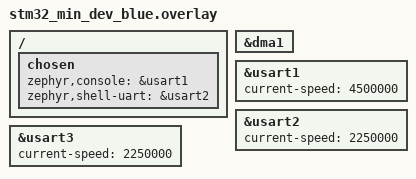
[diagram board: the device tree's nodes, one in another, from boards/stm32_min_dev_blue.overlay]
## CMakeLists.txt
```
cmake_minimum_required(VERSION 3.31)

find_package(Zephyr REQUIRED)
project(stm32f1-usb-gofast)

target_sources(app PRIVATE src/main.c src/usb.c)
```

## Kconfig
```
config GOFK_BULK_EP_MP
	int
	depends on USB_DEVICE_STACK
	default 512 if USB_DC_HAS_HS_SUPPORT
	default 64
	help
	  gofk bulk endpoint size

module = GOFK
module-str = gofk
source "subsys/logging/Kconfig.template.log_config"

source "Kconfig.zephyr"
```

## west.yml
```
manifest:
  remotes:
  - name: zephyrproject-rtos
    url-base: https://github.com/zephyrproject-rtos
  projects:
  - name: zephyr
    remote: zephyrproject-rtos
    revision: main
    import: true
```

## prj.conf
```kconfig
# Software Config

# Compilation

# Shell
CONFIG_SHELL=y
CONFIG_SHELL_MINIMAL=y

# Libraries
CONFIG_PICOLIBC=y
CONFIG_PICOLIBC_IO_FLOAT=n
CONFIG_PICOLIBC_IO_LONG_LONG=n
CONFIG_PICOLIBC_USE_MODULE=y
CONFIG_NET_BUF=y

# Timing
# CONFIG_TIMING_FUNCTIONS=y

# Debug
# CONFIG_ASSERT=n
# CONFIG_DEBUG=n
CONFIG_COMPILER_OPT="-ggdb3 -gdwarf-5 -Oz"

# console
# CONFIG_CONSOLE=n
# CONFIG_UART_CONSOLE=n

# logging
CONFIG_LOG=y
CONFIG_LOG_PRINTK=y
# CONFIG_LOG_SPEED=y
# CONFIG_LOG_BUFFER_SIZE=4096
# CONFIG_LOG_FRONTEND=y
# CONFIG_LOG_FRONTEND_DICT_UART=n
# CONFIG_LOG_FRONTEND_ONLY=y
# CONFIG_LOG_MEM_UTILIZATION=y
# CONFIG_LOG_FRONTEND_DICT_UART=y
# CONFIG_LOG_BACKEND_UART=y
# CONFIG_LOG_BACKEND_UART_ASYNC=y
# CONFIG_LOG_BACKEND_UART_OUTPUT_DICTIONARY_BIN=y
# CONFIG_LOG_BACKEND_UART_OUTPUT_DICTIONARY=y
# CONFIG_LOG_FMT_SECTION=y
# CONFIG_LOG_FRONTEND_DICT_UART=y
# CONFIG_LOG_FRONTEND_DICT_UART_BUFFER_SIZE=4096
# CONFIG_USB_DEVICE_LOG_LEVEL_INF=y
# CONFIG_USB_DEVICE_LOG_LEVEL_DBG=y
# CONFIG_USB_DEVICE_LOG_LEVEL_INF=y

# perf mon
# CONFIG_SCHED_THREAD_USAGE=y
# CONFIG_THREAD_ANALYZER=y
# CONFIG_THREAD_ANALYZER_USE_LOG=y
# CONFIG_THREAD_ANALYZER_AUTO=y
# CONFIG_THREAD_ANALYZER_AUTO_INTERVAL=10

# Hardware Config

# GPIO
CONFIG_GPIO=y

# UART
CONFIG_UART_ASYNC_API=n # need DMA
# CONFIG_UART_INTERRUPT_DRIVEN=n

# USB
CONFIG_USB_DEVICE_STACK=y
CONFIG_USB_DEVICE_VID=0x045a
CONFIG_USB_DEVICE_PID=0x6010
CONFIG_USB_DEVICE_MANUFACTURER="Pyongyang Chewing Gum Factory"
CONFIG_USB_DEVICE_PRODUCT="gofast"
```

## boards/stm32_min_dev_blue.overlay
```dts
/ {
	chosen {
		zephyr,console = &usart1;
		zephyr,shell-uart = &usart2;
	};
};

&dma1 {
	status = "okay";
};

// &usart1 {
// 	pinctrl-0 = <&usart1_tx_remap1_pb6 &usart1_rx_remap1_pb7>;
// 	current-speed = <3000000>;
// 	dmas = <&dma1 4 0x440>, <&dma1 5 0x480>;
// 	dma-names = "tx", "rx";
// };

&usart1 {
	current-speed = <4500000>;
};

&usart2 {
	current-speed = <2250000>;
};

&usart3 {
	current-speed = <2250000>;
};

// &usb {
// 	pinctrl-0 = <&usb_dm_pa11 &usb_dp_pa12>;
// 	pinctrl-1 = <&usb_dm_pa11_gpio_se0 &usb_dp_pa12_gpio_se0>;
// 	pinctrl-names = "default", "gpio_se0";
// 	num-bidir-endpoints = <3>;
// };
```

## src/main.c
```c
#include <stdio.h>

#include <zephyr/drivers/gpio.h>
#include <zephyr/kernel.h>
#include <zephyr/logging/log.h>
#include <zephyr/usb/usb_device.h>

LOG_MODULE_REGISTER(main);

/* 1000 msec = 1 sec */
#define SLEEP_TIME_MS 1000

/* The devicetree node identifier for the "led0" alias. */
#define LED0_NODE     DT_ALIAS(led0)

/*
 * A build error on this line means your board is unsupported.
 * See the sample documentation for information on how to fix this.
 */
static const struct gpio_dt_spec led = GPIO_DT_SPEC_GET(LED0_NODE, gpios);

int main(void) {
    int ret;
    bool led_state = true;

    LOG_INF("entered main.");

    ret = usb_enable(NULL);
    if (ret != 0) {
        LOG_ERR("Failed to enable USB");
        return 0;
    }
    LOG_INF("Enabled USB");

    if (!gpio_is_ready_dt(&led)) {
        return 0;
    }

    ret = gpio_pin_configure_dt(&led, GPIO_OUTPUT_ACTIVE);
    if (ret < 0) {
        return 0;
    }

    while (1) {
        ret = gpio_pin_toggle_dt(&led);
        if (ret < 0) {
            return 0;
        }

        led_state = !led_state;
        printf("LED state: %s\n", led_state ? "ON" : "OFF");
        k_msleep(SLEEP_TIME_MS);
    }
    return 0;
}
```

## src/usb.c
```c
#include <zephyr/logging/log.h>
LOG_MODULE_REGISTER(sfunc, LOG_LEVEL_INF);

#include <zephyr/drivers/usb/udc.h>
#include <zephyr/sys/byteorder.h>
#include <zephyr/usb/usbd.h>

/*
 * This file implements a simple USB function that echoes received data back to
 * the host using bulk endpoints.
 */

NET_BUF_POOL_FIXED_DEFINE(sfunc_pool, 1, 0, sizeof(struct udc_buf_info), NULL);

UDC_STATIC_BUF_DEFINE(sfunc_buf, 512);

struct sfunc_desc {
    struct usb_if_descriptor if0;
    struct usb_ep_descriptor if0_out_ep;
    struct usb_ep_descriptor if0_in_ep;
    struct usb_ep_descriptor if0_hs_out_ep;
    struct usb_ep_descriptor if0_hs_in_ep;
    struct usb_desc_header nil_desc;
};

#define SAMPLE_FUNCTION_ENABLED 0

struct sfunc_data {
    struct sfunc_desc *const desc;
    const struct usb_desc_header **const fs_desc;
    const struct usb_desc_header **const hs_desc;
    atomic_t state;
};

static uint8_t sfunc_get_bulk_out(struct usbd_class_data *const c_data) {
    struct sfunc_data *data      = usbd_class_get_private(c_data);
    struct usbd_context *uds_ctx = usbd_class_get_ctx(c_data);
    struct sfunc_desc *desc      = data->desc;

    if (usbd_bus_speed(uds_ctx) == USBD_SPEED_HS) {
        return desc->if0_hs_out_ep.bEndpointAddress;
    }

    return desc->if0_out_ep.bEndpointAddress;
}

static uint8_t sfunc_get_bulk_in(struct usbd_class_data *const c_data) {
    struct sfunc_data *data      = usbd_class_get_private(c_data);
    struct usbd_context *uds_ctx = usbd_class_get_ctx(c_data);
    struct sfunc_desc *desc      = data->desc;

    if (usbd_bus_speed(uds_ctx) == USBD_SPEED_HS) {
        return desc->if0_hs_in_ep.bEndpointAddress;
    }

    return desc->if0_in_ep.bEndpointAddress;
}

static int sfunc_request_handler(struct usbd_class_data *c_data, struct net_buf *buf, int err) {
    struct usbd_context *uds_ctx = usbd_class_get_ctx(c_data);
    struct sfunc_data *data      = usbd_class_get_private(c_data);
    struct udc_buf_info *bi      = NULL;

    bi = (struct udc_buf_info *)net_buf_user_data(buf);
    LOG_INF("Transfer finished %p -> ep 0x%02x, len %u, err %d", (void *)c_data, bi->ep, buf->len,
            err);

    if (atomic_test_bit(&data->state, SAMPLE_FUNCTION_ENABLED) && err == 0) {
        uint8_t ep = bi->ep;

        memset(bi, 0, sizeof(struct udc_buf_info));

        if (ep == sfunc_get_bulk_in(c_data)) {
            bi->ep = sfunc_get_bulk_out(c_data);
            net_buf_reset(buf);
        } else {
            bi->ep = sfunc_get_bulk_in(c_data);
        }

        if (usbd_ep_enqueue(c_data, buf)) {
            LOG_ERR("Failed to enqueue buffer");
            usbd_ep_buf_free(uds_ctx, buf);
        }
    } else {
        LOG_ERR("Function is disabled or transfer failed");
        usbd_ep_buf_free(uds_ctx, buf);
    }

    return 0;
}

static void *sfunc_get_desc(struct usbd_class_data *const c_data, const enum usbd_speed speed) {
    struct sfunc_data *data = usbd_class_get_private(c_data);

    if (speed == USBD_SPEED_HS) {
        return data->hs_desc;
    }

    return data->fs_desc;
}

struct net_buf *sfunc_buf_alloc(struct usbd_class_data *const c_data, const uint8_t ep) {
    struct usbd_context *uds_ctx = usbd_class_get_ctx(c_data);
    struct net_buf *buf          = NULL;
    struct udc_buf_info *bi;
    size_t size;

    if (usbd_bus_speed(uds_ctx) == USBD_SPEED_HS) {
        size = 512U;
    } else {
        size = 64U;
    }

    buf = net_buf_alloc_with_data(&sfunc_pool, sfunc_buf, size, K_NO_WAIT);
    net_buf_reset(buf);
    if (!buf) {
        return NULL;
    }

    bi     = udc_get_buf_info(buf);
    bi->ep = ep;

    return buf;
}

static void sfunc_enable(struct usbd_class_data *const c_data) {
    struct sfunc_data *data      = usbd_class_get_private(c_data);
    struct usbd_context *uds_ctx = usbd_class_get_ctx(c_data);
    struct net_buf *buf;

    LOG_INF("Configuration enabled");

    if (!atomic_test_and_set_bit(&data->state, SAMPLE_FUNCTION_ENABLED)) {
        buf = sfunc_buf_alloc(c_data, sfunc_get_bulk_out(c_data));
        if (buf == NULL) {
            LOG_ERR("Failed to allocate buffer");
            return;
        }

        if (usbd_ep_enqueue(c_data, buf)) {
            LOG_ERR("Failed to enqueue buffer");
            usbd_ep_buf_free(uds_ctx, buf);
        }
    }
}

static void sfunc_disable(struct usbd_class_data *const c_data) {
    struct sfunc_data *data = usbd_class_get_private(c_data);

    atomic_clear_bit(&data->state, SAMPLE_FUNCTION_ENABLED);
    LOG_INF("Configuration disabled");
}

static int sfunc_init(struct usbd_class_data *c_data) {
    LOG_DBG("Init class instance %p", (void *)c_data);

    return 0;
}

struct usbd_class_api sfunc_api = {
    .request  = sfunc_request_handler,
    .get_desc = sfunc_get_desc,
    .enable   = sfunc_enable,
    .disable  = sfunc_disable,
    .init     = sfunc_init,
};

#define SFUNC_DESCRIPTOR_DEFINE(n, _)                                   \
    static struct sfunc_desc sfunc_desc_##n = {                         \
        /* Interface descriptor 0 */                                    \
        .if0 =                                                          \
            {                                                           \
                .bLength            = sizeof(struct usb_if_descriptor), \
                .bDescriptorType    = USB_DESC_INTERFACE,               \
                .bInterfaceNumber   = 0,                                \
                .bAlternateSetting  = 0,                                \
                .bNumEndpoints      = 2,                                \
                .bInterfaceClass    = USB_BCC_VENDOR,                   \
                .bInterfaceSubClass = 0,                                \
                .bInterfaceProtocol = 0,                                \
                .iInterface         = 0,                                \
            },                                                          \
                                                                        \
        /* Endpoint OUT */                                              \
        .if0_out_ep =                                                   \
            {                                                           \
                .bLength          = sizeof(struct usb_ep_descriptor),   \
                .bDescriptorType  = USB_DESC_ENDPOINT,                  \
                .bEndpointAddress = 0x01,                               \
                .bmAttributes     = USB_EP_TYPE_BULK,                   \
                .wMaxPacketSize   = sys_cpu_to_le16(64U),               \
                .bInterval        = 0x00,                               \
            },                                                          \
                                                                        \
        /* Endpoint IN */                                               \
        .if0_in_ep =                                                    \
            {                                                           \
                .bLength          = sizeof(struct usb_ep_descriptor),   \
                .bDescriptorType  = USB_DESC_ENDPOINT,                  \
                .bEndpointAddress = 0x81,                               \
                .bmAttributes     = USB_EP_TYPE_BULK,                   \
                .wMaxPacketSize   = sys_cpu_to_le16(64U),               \
                .bInterval        = 0x00,                               \
            },                                                          \
                                                                        \
        /* High-speed Endpoint OUT */                                   \
        .if0_hs_out_ep =                                                \
            {                                                           \
                .bLength          = sizeof(struct usb_ep_descriptor),   \
                .bDescriptorType  = USB_DESC_ENDPOINT,                  \
                .bEndpointAddress = 0x01,                               \
                .bmAttributes     = USB_EP_TYPE_BULK,                   \
                .wMaxPacketSize   = sys_cpu_to_le16(512),               \
                .bInterval        = 0x00,                               \
            },                                                          \
                                                                        \
        /* High-speed Endpoint IN */                                    \
        .if0_hs_in_ep =                                                 \
            {                                                           \
                .bLength          = sizeof(struct usb_ep_descriptor),   \
                .bDescriptorType  = USB_DESC_ENDPOINT,                  \
                .bEndpointAddress = 0x81,                               \
                .bmAttributes     = USB_EP_TYPE_BULK,                   \
                .wMaxPacketSize   = sys_cpu_to_le16(512),               \
                .bInterval        = 0x00,                               \
            },                                                          \
                                                                        \
        /* Termination descriptor */                                    \
        .nil_desc =                                                     \
            {                                                           \
                .bLength         = 0,                                   \
                .bDescriptorType = 0,                                   \
            },                                                          \
    };                                                                  \
                                                                        \
    const static struct usb_desc_header *sfunc_fs_desc_##n[] = {        \
        (struct usb_desc_header *)&sfunc_desc_##n.if0,                  \
        (struct usb_desc_header *)&sfunc_desc_##n.if0_in_ep,            \
        (struct usb_desc_header *)&sfunc_desc_##n.if0_out_ep,           \
        (struct usb_desc_header *)&sfunc_desc_##n.nil_desc,             \
    };                                                                  \
                                                                        \
    const static struct usb_desc_header *sfunc_hs_desc_##n[] = {        \
        (struct usb_desc_header *)&sfunc_desc_##n.if0,                  \
        (struct usb_desc_header *)&sfunc_desc_##n.if0_hs_in_ep,         \
        (struct usb_desc_header *)&sfunc_desc_##n.if0_hs_out_ep,        \
        (struct usb_desc_header *)&sfunc_desc_##n.nil_desc,             \
    };

#define SFUNC_FUNCTION_DATA_DEFINE(n, _)                             \
    static struct sfunc_data sfunc_data_##n = {                      \
        .desc    = &sfunc_desc_##n,                                  \
        .fs_desc = sfunc_fs_desc_##n,                                \
        .hs_desc = sfunc_hs_desc_##n,                                \
    };                                                               \
                                                                     \
    USBD_DEFINE_CLASS(sfunc_##n, &sfunc_api, &sfunc_data_##n, NULL);

LISTIFY(1, SFUNC_DESCRIPTOR_DEFINE, ())
LISTIFY(1, SFUNC_FUNCTION_DATA_DEFINE, ())
```
